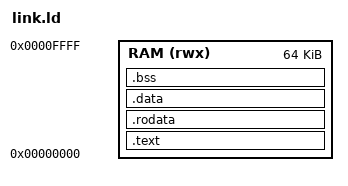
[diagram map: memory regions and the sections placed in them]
ENTRY(_start)

MEMORY
{
    RAM (rwx) : ORIGIN = 0x00000000, LENGTH = 64K
}

SECTIONS
{
    .text : {
        *(.text._start)
        *(.text*)
    } > RAM

    .rodata : { *(.rodata*) } > RAM
    .data   : { *(.data*)   } > RAM
    .bss    : { *(.bss*)    } > RAM

    _stack_top = ORIGIN(RAM) + LENGTH(RAM);
}
